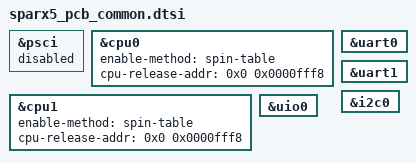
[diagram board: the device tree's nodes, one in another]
// SPDX-License-Identifier: (GPL-2.0+ OR MIT)
/*
 * Copyright (c) 2020 Microchip Technology Inc. and its subsidiaries.
 */

/dts-v1/;
#include "sparx5.dtsi"

&psci {
	status = "disabled";
};

&cpu0 {
	enable-method = "spin-table";
	cpu-release-addr = <0x0 0x0000fff8>;
};

&cpu1 {
	enable-method = "spin-table";
	cpu-release-addr = <0x0 0x0000fff8>;
};

&uart0 {
	status = "okay";
};

&uart1 {
	status = "okay";
};

&i2c0 {
	status = "okay";
};

/* Used by symreg tool, DO NOT upstream */
&uio0 {
	status = "okay";
};
